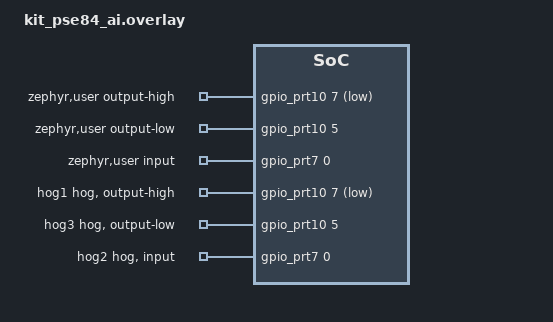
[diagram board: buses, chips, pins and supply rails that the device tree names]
/*
 * SPDX-FileCopyrightText: Copyright (c) 2026 Infineon Technologies AG,
 * SPDX-FileCopyrightText: or an affiliate of Infineon Technologies AG. All rights reserved.
 *
 * SPDX-License-Identifier: Apache-2.0
 */

#include <zephyr/dt-bindings/gpio/gpio.h>

/ {
	zephyr,user {
		output-high-gpios = <&gpio_prt10 7 GPIO_ACTIVE_LOW>;
		output-low-gpios = <&gpio_prt10 5 GPIO_ACTIVE_HIGH>;
		input-gpios = <&gpio_prt7 0 GPIO_ACTIVE_HIGH>;
	};
};

&gpio_prt10 {
	hog1 {
		gpio-hog;
		gpios = <7 GPIO_ACTIVE_LOW>;
		output-high;
	};

	hog3 {
		gpio-hog;
		gpios = <5 GPIO_ACTIVE_HIGH>;
		output-low;
	};
};

&gpio_prt7 {
	hog2 {
		gpio-hog;
		gpios = <0 GPIO_ACTIVE_HIGH>;
		input;
	};
};
